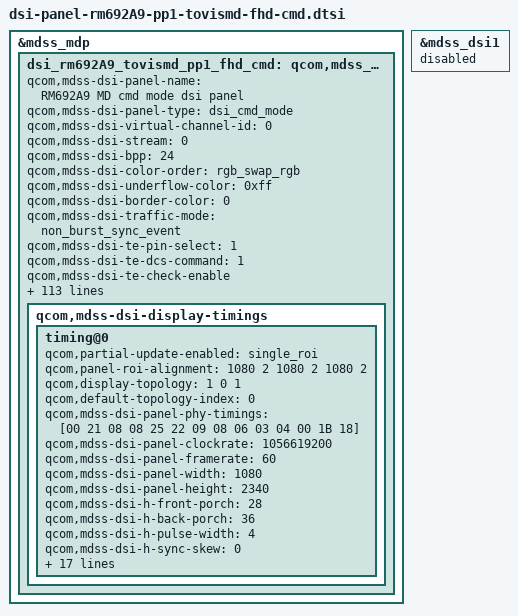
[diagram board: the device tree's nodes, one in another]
/* Copyright (c) 2014, Code Aurora Forum. All rights reserved.
 *
 * This program is free software; you can redistribute it and/or modify
 * it under the terms of the GNU General Public License version 2 and
 * only version 2 as published by the Free Software Foundation.
 *
 * This program is distributed in the hope that it will be useful,
 * but WITHOUT ANY WARRANTY; without even the implied warranty of
 * MERCHANTABILITY or FITNESS FOR A PARTICULAR PURPOSE.  See the
 * GNU General Public License for more details.
 */

&mdss_mdp {
    dsi_rm692A9_tovismd_pp1_fhd_cmd: qcom,mdss_dsi_rm692A9_tovismd_pp1_fhd_cmd {
		qcom,mdss-dsi-panel-name = "RM692A9 MD cmd mode dsi panel";
		qcom,mdss-dsi-panel-type = "dsi_cmd_mode";
		qcom,mdss-dsi-virtual-channel-id = <0>;
		qcom,mdss-dsi-stream = <0>;
		qcom,mdss-dsi-bpp = <24>;
		qcom,mdss-dsi-color-order = "rgb_swap_rgb";
		qcom,mdss-dsi-underflow-color = <0xff>;
		qcom,mdss-dsi-border-color = <0>;
		qcom,mdss-dsi-traffic-mode = "non_burst_sync_event";
		qcom,mdss-dsi-te-pin-select = <1>;
		qcom,mdss-dsi-te-dcs-command = <1>;
		qcom,mdss-dsi-te-check-enable;
		qcom,mdss-dsi-te-using-te-pin;
		qcom,mdss-dsi-lane-map = "lane_map_0123";
		qcom,mdss-dsi-bllp-eof-power-mode;
		qcom,mdss-dsi-bllp-power-mode;
		qcom,mdss-dsi-lane-0-state;
		qcom,mdss-dsi-lane-1-state;
		qcom,mdss-dsi-lane-2-state;
		qcom,mdss-dsi-lane-3-state;
		qcom,mdss-dsi-reset-sequence = <1 10>, <0 2>, <1 10>;
		qcom,mdss-dsi-dma-trigger = "trigger_sw";
		qcom,mdss-dsi-mdp-trigger = "none";
		qcom,mdss-dsi-wr-mem-start = <0x2c>;
		qcom,mdss-dsi-wr-mem-continue = <0x3c>;
		qcom,mdss-dsi-lp11-init;
		qcom,mdss-dsi-tx-eot-append;
		qcom,ulps-enabled;
		qcom,mdss-dsi-panel-hdr-enabled;
		qcom,mdss-dsi-panel-hdr-color-primaries = <14880 15935 32435 16555 14945 30910 7790 3415>;
		qcom,mdss-dsi-panel-peak-brightness = <5643000>;
		qcom,mdss-dsi-panel-blackness-level = <6134>;
		qcom,esd-check-enabled;
		qcom,mdss-dsi-panel-status-check-mode = "te_signal_check";

		lge,blmap = <
			0
			7 7 7 7 7 7 7 7 7 7 7 8 8 9 9 10 10 11 11 12
			12 13 13 13 14 14 15 15 16 16 17 17 18 18 19 19 21 22 24 26
			28 29 31 33 34 36 38 40 41 43 45 47 48 50 52 53 55 57 59 60
			62 65 68 71 75 78 81 84 87 90 93 96 100 103 106 109 112 115 118 121
			125 129 134 139 137 142 147 151 156 161 166 171 176 180 185 190 195 200 205 209
			214 219 224 229 234 238 243 248 254 259 265 270 276 282 287 293 299 304 310 315
			321 327 332 338 343 349 355 360 366 372 377 383 388 394 402 410 418 426 434 442
			449 455 463 471 479 487 495 503 510 518 526 534 542 550 558 566 574 582 592 601
			611 620 629 639 648 657 667 676 685 695 704 713 723 732 741 751 760 769 779 788
			797 807 816 828 840 852 864 876 888 900 912 924 936 948 960 972 984 996 1008 1020
			1032 1044 1056 1068 1080 1092 1104 1117 1130 1143 1156 1170 1183 1196 1209 1222 1235 1248 1261 1275
			1288 1301 1314 1327 1340 1353 1366 1380 1393 1406 1419 1432 1448 1464 1480 1497 1513 1529 1545 1561
			1577 1593 1609 1626 1642 1658 1674 1690 1706 1722 1738 1755 1771 1787 1803 1806 1809 1812 1816 1819
			1822 1825 1828 1831 1834 1837 1841 1844 1847 1850 1853 1856 1859 1862 1866 1869 1872 1875 1878 1881
			1884 1887 1891 1894 1897 1900 1925 1950 1975 2000 2025 2050 2075 2100 2125 2150 2175 2200 2225 2250
			2275 2300 2311 2322 2333 2344 2356 2367 2378 2389 2400 2411 2422 2433 2444 2456 2467 2478 2489 2500
			2538 2577 2615 2654 2692 2731 2769 2808 2846 2885 2923 2962 3000 3038 3077 3115 3154 3192 3231 3269
			3308 3346 3385 3423 3462 3500 3531 3563 3594 3625 3657 3688 3719 3751 3782 3813 3844 3876 3907 3938
			3970 4001 4032 4064 4095
			>;
		lge,blmap-ve = <
			0
			7 7 7 7 7 7 7 7 7 7 7 8 8 9 9 10 10 11 11 12
			12 13 13 13 14 14 15 15 16 16 17 17 18 18 19 19 21 22 24 26
			28 29 31 33 34 36 38 40 41 43 45 47 48 50 52 53 55 57 59 60
			62 65 68 71 75 78 81 84 87 90 93 96 100 103 106 109 112 115 118 121
			125 129 134 139 137 142 147 151 156 161 166 171 176 180 185 190 195 200 205 209
			214 219 224 229 234 238 243 248 254 259 265 270 276 282 287 293 299 304 310 315
			321 327 332 338 343 349 355 360 366 372 377 383 388 394 402 410 418 426 434 442
			449 455 463 471 479 487 495 503 510 518 526 534 542 550 558 566 574 582 592 601
			611 620 629 639 648 657 667 676 685 695 704 713 723 732 741 751 760 769 779 788
			797 807 816 828 840 852 864 876 888 900 912 924 936 948 960 972 984 996 1008 1020
			1032 1044 1056 1068 1080 1092 1104 1117 1130 1143 1156 1170 1183 1196 1209 1222 1235 1248 1261 1275
			1288 1301 1314 1327 1340 1353 1366 1380 1393 1406 1419 1432 1448 1464 1480 1497 1513 1529 1545 1561
			1577 1593 1609 1626 1642 1658 1674 1690 1706 1722 1738 1755 1771 1787 1803 1806 1809 1812 1816 1819
			1822 1825 1828 1831 1834 1837 1841 1844 1847 1850 1853 1856 1859 1862 1866 1869 1872 1875 1878 1881
			1884 1887 1891 1894 1897 1900 1925 1950 1975 2000 2025 2050 2075 2100 2125 2150 2175 2200 2225 2250
			2275 2300 2311 2322 2333 2344 2356 2367 2378 2389 2400 2411 2422 2433 2444 2456 2467 2478 2489 2500
			2538 2577 2615 2654 2692 2731 2769 2808 2846 2885 2923 2962 3000 3038 3077 3115 3154 3192 3231 3269
			3308 3346 3385 3423 3462 3500 3531 3563 3594 3625 3657 3688 3719 3751 3782 3813 3844 3876 3907 3938
			3970 4001 4032 4064 4095
			>;
		lge,blmap-ex = <
			0
			2 2 2 2 2 2 2 2 2 3 4 5 6 7 8 10 11 12 13 14
			15 16 17 18 19 20 21 22 23 25 26 27 28 29 30 31 35 38 42 45
			49 52 56 59 63 66 70 73 77 80 84 87 91 94 98 101 105 108 112 115
			119 122 126 129 133 136 140 143 147 150 154 157 161 164 168 172 176 180 184 188
			192 196 200 204 208 212 215 219 223 227 231 235 239 243 247 251 255 255 255 255
			255 255 255 255 255 255 255 255 255 255 255 255 255 255 255 255 255 255 255 255
			255 255 255 255 255 255 255 255 255 255 255 255 255 255 255 255 255 255 255 255
			255 255 255 255 255 255 255 255 255 255 255 255 255 255 255 255 255 255 255
		>;
		lge,blmap-hdr = <
			0
			7 7 7 7 7 7 7 7 7 7 7 8 8 9 9 10 10 11 11 12
			12 13 13 13 14 14 15 15 16 16 17 17 18 18 19 19 21 22 24 26
			28 29 31 33 34 36 38 40 41 43 45 47 48 50 52 53 55 57 59 60
			62 65 68 71 75 78 81 84 87 90 93 96 100 103 106 109 112 115 118 121
			125 129 134 139 137 142 147 151 156 161 166 171 176 180 185 190 195 200 205 209
			214 219 224 229 234 238 243 248 254 259 265 270 276 282 287 293 299 304 310 315
			321 327 332 338 343 349 355 360 366 372 377 383 388 394 402 410 418 426 434 442
			449 455 463 471 479 487 495 503 510 518 526 534 542 550 558 566 574 582 592 601
			611 620 629 639 648 657 667 676 685 695 704 713 723 732 741 751 760 769 779 788
			797 807 816 828 840 852 864 876 888 900 912 924 936 948 960 972 984 996 1008 1020
			1032 1044 1056 1068 1080 1092 1104 1117 1130 1143 1156 1170 1183 1196 1209 1222 1235 1248 1261 1275
			1288 1301 1314 1327 1340 1353 1366 1380 1393 1406 1419 1432 1448 1464 1480 1497 1513 1529 1545 1561
			1577 1593 1609 1626 1642 1658 1674 1690 1706 1722 1738 1755 1771 1787 1803 1806 1809 1812 1816 1819
			1822 1825 1828 1831 1834 1837 1841 1844 1847 1850 1853 1856 1859 1862 1866 1869 1872 1875 1878 1881
			1884 1887 1891 1894 1897 1900 1925 1950 1975 2000 2025 2050 2075 2100 2125 2150 2175 2200 2225 2250
			2275 2300 2311 2322 2333 2344 2356 2367 2378 2389 2400 2411 2422 2433 2444 2456 2467 2478 2489 2500
			2538 2577 2615 2654 2692 2731 2769 2808 2846 2885 2923 2962 3000 3038 3077 3115 3154 3192 3231 3269
			3308 3346 3385 3423 3462 3500 3531 3563 3594 3625 3657 3688 3719 3751 3782 3813 3844 3876 3907 3938
			3970 4001 4032 4064 4095
		>;
		qcom,mdss-pan-physical-width-dimension = <68>;
		qcom,mdss-pan-physical-height-dimension = <142>;

		qcom,mdss-dsi-t-clk-post = <0x18>;
		qcom,mdss-dsi-t-clk-pre = <0x1B>;

		lge,use-ambient;
		lge,aod-interface-data = "semi-partial", "semi-partial", "semi-partial";
		lge,mdss-dsi-nolp-command = [
			15 01 00 00 00 00 02 FE 00
			05 01 00 00 64 00 01 38
			05 01 00 00 20 00 01 28
			15 01 00 00 00 00 02 FE D0
			15 01 00 00 14 00 02 30 00
			15 01 00 00 00 00 02 FE 20
			15 01 00 00 00 00 02 5F 01
			15 01 00 00 00 00 02 FE 00
			05 01 00 00 20 00 01 29
		];
		lge,mdss-dsi-nolp-command-state = "dsi_lp_mode";

//		lge,mdss-dsi-aod-area-command = [
//			15 01 00 00 00 00 02 FE 00
//			39 01 00 00 00 00 05 30 00 00 04 37
//		];
//		lge,mdss-dsi-aod-area-command-state = "dsi_lp_mode";

		lge,mdss-dsi-lp2-command = [
			15 01 00 00 00 00 02 FE 00
			05 01 00 00 20 00 01 28
			15 01 00 00 00 00 02 FE D0
			15 01 00 00 14 00 02 30 03
			15 01 00 00 00 00 02 FE 20
			15 01 00 00 00 00 02 5F 07
			15 01 00 00 00 00 02 FE 00
			05 01 00 00 64 00 01 29
			05 01 00 00 20 00 01 39
		];
		lge,mdss-dsi-lp2-command-state = "dsi_lp_mode";

		lge,use-line-detect;
		lge,detect-vert-line-restore-command = [
			15 01 00 00 00 00 02 FE 40
			15 01 00 00 00 00 02 2D 28
			15 01 00 00 00 00 02 2F 28
			15 01 00 00 00 00 02 30 32
			15 01 00 00 00 00 02 31 32
			15 01 00 00 00 00 02 FE 00
		];
		lge,detect-vert-line-restore-command-state = "dsi_lp_mode";
		lge,detect-black-vert-line-command = [
			15 01 00 00 00 00 02 FE 40
			15 01 00 00 00 00 02 2D 14
			15 01 00 00 00 00 02 2F 14
			15 01 00 00 00 00 02 30 46
			15 01 00 00 00 00 02 31 46
			15 01 00 00 00 00 02 FE 00
		];
		lge,detect-black-vert-line-command-state = "dsi_lp_mode";
		lge,detect-white-vert-line-command = [
			15 01 00 00 00 00 02 FE 40
			15 01 00 00 00 00 02 2D 46
			15 01 00 00 00 00 02 2F 46
			15 01 00 00 00 00 02 30 1E
			15 01 00 00 00 00 02 31 1E
			15 01 00 00 00 00 02 FE 00
		];
		lge,detect-white-vert-line-command-state = "dsi_lp_mode";

		lge,use-color-manager;
		lge,color-manager-default-status = <1>;
		lge,mdss-dsi-color-manager-mode-table = <0 1>, <1 1>, <2 1>, <3 1>;
		lge,digital-gamma-absent;

		lge,mdss-dsi-disp-ctrl-command-1 = [
			15 01 00 00 00 00 02 FE 00
			15 01 00 00 00 00 02 5C 00
			15 01 00 00 00 00 02 FE 80
			15 01 00 00 00 00 02 00 4F
			15 01 00 00 00 00 02 05 00
			15 01 00 00 00 00 02 FE 00
		];
		lge,mdss-dsi-disp-ctrl-command-1-state = "dsi_lp_mode";
		lge,mdss-dsi-disp-ctrl-command-2 = [
			15 01 00 00 00 00 02 FE 12
			15 01 00 00 00 00 02 83 10
			15 01 00 00 00 00 02 84 08
			15 01 00 00 00 00 02 FE 00
		];
		lge,mdss-dsi-disp-ctrl-command-2-state = "dsi_lp_mode";

		lge,color-mode-cmds-dummy = [
			/* CE setting */
			15 00 00 00 00 00 02 FE 00
			15 00 00 00 00 00 02 5A 0B
			15 00 00 00 00 00 02 5C 00
			/* HUE, SAT enable/disable */
			15 00 00 00 00 00 02 FE 80
			15 00 00 00 00 00 02 00 4F
			/* CE gain */
			15 00 00 00 00 00 02 08 44
			15 00 00 00 00 00 02 09 20
			15 00 00 00 00 00 02 0A EE
			15 00 00 00 00 00 02 0B 02
			15 00 00 00 00 00 02 0C 20
			15 00 00 00 00 00 02 0D F0
			15 00 00 00 00 00 02 0E CF
			15 00 00 00 00 00 02 0F 07
			15 00 00 00 00 00 02 14 CF
			15 00 00 00 00 00 02 15 04
			15 00 00 00 00 00 02 16 F3
			15 00 00 00 00 00 02 17 D7
			15 00 00 00 00 00 02 18 CC
			15 00 00 00 00 00 02 19 7D
			15 00 00 00 00 00 02 1A E3
			15 00 00 00 00 00 02 1B 07
			/* Default CM */
			15 00 00 00 00 00 02 FE 10
			15 00 00 00 00 00 02 00 FF
			15 00 00 00 00 00 02 01 07
			15 00 00 00 00 00 02 02 00
			15 00 00 00 00 00 02 03 00
			15 00 00 00 00 00 02 04 00
			15 00 00 00 00 00 02 05 00
			15 00 00 00 00 00 02 06 FF
			15 00 00 00 00 00 02 07 E7
			15 00 00 00 00 00 02 08 00
			15 00 00 00 00 00 02 09 03
			15 00 00 00 00 00 02 0A 20
			15 00 00 00 00 00 02 0B 00
			15 00 00 00 00 00 02 0C FC
			15 00 00 00 00 00 02 0D 07
			15 00 00 00 00 00 02 FE 12
			15 00 00 00 00 00 02 84 08
			15 01 00 00 00 00 02 FE 00
		];
		lge,color-mode-cmds-dummy-state = "dsi_lp_mode";

		lge,use-color-manager-lut;
		lge,cm-lut-screen-mode-set-name = "def", "cin", "pho", "web", "spo", "gam", "exp";
		lge,cm-lut-screen-mode-set-cnt = <39>;
		lge,cm-lut-screen-mode-set = [
			00 0B 00 80 4F 44 20 EE 02 20 F0 CF 07 CF 04 F3 D7 CC 7D E3 07 10 FF 07 00 00 00 00 FF E7 00 03 20 00 FC 07 12 08 00
			00 0B 00 80 4F 00 FF FF 00 F0 EF C3 01 0F 0F 03 D2 EE 3F 85 07 10 53 07 08 3B 90 00 23 77 02 00 90 00 9F 06 12 00 00
			00 0B 00 80 4F F0 F0 C0 C0 22 F2 55 07 1F 00 03 43 00 EF 01 0C 10 FF 07 00 35 90 06 BD 46 02 28 80 03 46 06 12 00 00
			00 0B 00 80 4F F0 FF F0 00 FF FF D1 00 0F 0F 03 02 00 1F 05 04 10 0D 56 1E 36 F0 04 E1 36 02 1D 00 08 07 06 12 00 00
			00 0B 00 80 4F 46 22 EE 15 21 F0 CF 07 CF 04 F3 C7 CC 7D E3 07 10 2E 07 00 00 00 00 40 E7 00 03 30 00 FB 07 12 00 00
			00 0B 00 80 4F 46 40 FE 12 21 F0 CF 07 CF 04 F3 C7 CC 7D E3 07 10 7F 07 00 00 00 00 95 D7 00 03 30 00 FA 07 12 00 00
			00 0B 00 80 4F 44 20 EE 02 20 F0 CF 07 CF 04 F3 D7 CC 7D E3 07 10 FF 07 00 00 00 00 FF E7 00 03 20 00 FC 07 12 08 00
		];

		lge,cm-lut-saturation-cnt = <13>;
		lge,cm-lut-saturation = [
			00 0B 00 80 4F D9 DD DC DD DD CD 01 00
			00 0B 00 80 4F EC EF FE FF FF DF 01 00
			00 0B 00 80 4F 44 20 EE 02 20 F0 CF 07
			00 0B 00 80 4F FF 44 FF 23 44 B2 CD 0F
			00 0B 00 80 4F 1F 56 01 56 56 F3 FF 0F
		];

		lge,cm-lut-sharpness-cnt = <1>;
		lge,cm-lut-sharpness = [08 12 1C 26 30];

		lge,cm-lut-rgb-hue-cnt = <14>;
		lge,cm-lut-rgb-hue = [
			E0 25 01 F5 20 09 72 47 00 01 00 0C 50 06
			80 26 01 F5 20 09 72 A7 00 01 00 0C C0 06
			F0 26 01 F5 20 09 73 07 00 01 00 0C 40 07
			FF 26 01 F5 20 09 11 87 00 01 00 0C 3A 07
			FF 26 01 F5 20 09 7F 86 00 01 00 0C 30 07
			5A 06 01 7E 00 05 B8 47 00 00 F0 05 A4 06
			E8 06 01 7E 00 05 CF A7 00 00 F0 05 17 07
			68 07 01 7E 00 05 B9 07 00 00 F0 05 A3 07
			30 07 01 7E 00 05 00 87 00 00 F0 05 4F 07
			30 07 01 7E 00 05 84 96 00 00 F0 05 3F 07
			EB 06 00 00 00 00 FF 67 00 00 30 00 04 07
			77 07 00 00 00 00 FF 77 00 01 30 00 7C 07
			FF 07 00 00 00 00 FF E7 00 03 20 00 FC 07
			FF 07 00 00 00 00 9B 77 00 01 30 00 F4 07
			FF 07 00 00 00 00 21 87 00 01 30 00 F4 07
			35 06 0A 00 40 01 8F 67 04 43 E0 00 99 06
			C0 06 0A 00 40 01 8F 77 04 43 E0 00 10 07
			60 07 0A 00 40 01 8F E7 04 43 E0 00 B0 07
			60 07 0A 00 40 01 50 77 04 43 E0 00 AF 07
			60 07 0A 00 40 01 DE 76 04 43 E0 00 A7 07
			BA 75 12 00 F0 00 5D 67 08 7F E0 00 69 06
			4A 76 12 00 F0 00 5D 77 08 7F E0 00 DE 06
			EA 76 12 00 F0 00 5D E7 08 7F E0 00 73 07
			EA 76 12 00 F0 00 16 77 08 7F E0 00 70 07
			EA 76 12 00 F0 00 97 76 08 7F E0 00 6A 07
		];

		/* Video Enahnacement */
		lge,mdss-dsi-ve-on-command = [
			15 01 00 00 00 00 02 FE 00
			15 01 00 00 00 00 02 6A A8
		];
		lge,mdss-dsi-ve-on-command-state = "dsi_lp_mode";

		lge,mdss-dsi-ve-off-command = [
			15 01 00 00 00 00 02 FE 00
			15 01 00 00 00 00 02 6A 50
		];
		lge,mdss-dsi-ve-off-command-state = "dsi_lp_mode";

		lge,disp-br-ctrl-ext-supported;
		lge,ddic-dsi-br-ctrl-ext-command = [
			15 01 00 00 00 00 02 FE 72
			15 01 00 00 00 00 02 69 00
			15 01 00 00 00 00 02 FE 00
		];
		lge,ddic-dsi-br-ctrl-ext-command-state = "dsi_lp_mode";

		/* FP LHBM */
		lge,use-fp-lhbm;
		//lge,is-fp-hbm-mode;
		lge,fp-hbm-mode-backlight-level = <0x70B>;
		lge,mdss-dsi-fp-lhbm-command = [
			15 01 00 00 00 00 02 FE 00
			15 01 00 00 14 00 02 83 00
		];
		lge,mdss-dsi-fp-lhbm-command-state = "dsi_lp_mode";

		lge,mdss-dsi-fp-lhbm-ready-command = [
			15 00 00 00 00 00 02 FE 74
			15 00 00 00 00 00 02 3D FF
			15 00 00 00 00 00 02 46 FF
			15 00 00 00 00 00 02 41 FF
			15 01 00 00 00 00 02 3A FF
			15 00 00 00 00 00 02 FE D0
			15 01 00 00 00 00 02 99 03
			15 01 00 00 00 00 02 FE 00
		];
		lge,mdss-dsi-fp-lhbm-ready-command-state = "dsi_lp_mode";

		lge,mdss-dsi-fp-lhbm-exit-command = [
			15 00 00 00 00 00 02 FE 74 /*LHBM Exit*/
			15 00 00 00 00 00 02 3D 4F
			15 00 00 00 00 00 02 46 00
			15 00 00 00 00 00 02 41 00
			15 01 00 00 00 00 02 3A F4
			15 00 00 00 00 00 02 FE D0
			15 01 00 00 00 00 02 99 01
			15 01 00 00 00 00 02 FE 00
		];
		lge,mdss-dsi-fp-lhbm-exit-command-state = "dsi_lp_mode";

		qcom,mdss-dsi-display-timings {
			timing@0{
				qcom,partial-update-enabled = "single_roi";
				qcom,panel-roi-alignment = <1080 2 1080 2 1080 2>;
				qcom,display-topology = <1 0 1>;
				qcom,default-topology-index = <0>;
				qcom,mdss-dsi-panel-phy-timings = [00 21 08 08 25 22 09 08 06 03 04 00 1B 18];
				qcom,mdss-dsi-panel-clockrate = <1056619200>;
				qcom,mdss-dsi-panel-framerate = <60>;
				qcom,mdss-dsi-panel-width = <1080>;
				qcom,mdss-dsi-panel-height = <2340>;
				qcom,mdss-dsi-h-front-porch = <28>;
				qcom,mdss-dsi-h-back-porch = <36>;
				qcom,mdss-dsi-h-pulse-width = <4>;
				qcom,mdss-dsi-h-sync-skew = <0>;
				qcom,mdss-dsi-v-back-porch = <4>;
				qcom,mdss-dsi-v-front-porch = <12>;
				qcom,mdss-dsi-v-pulse-width = <4>;
				qcom,mdss-dsi-h-left-border = <0>;
				qcom,mdss-dsi-h-right-border = <0>;
				qcom,mdss-dsi-v-top-border = <0>;
				qcom,mdss-dsi-v-bottom-border = <0>;
				qcom,mdss-mdp-transfer-time-us = <15200>;

				qcom,mdss-dsi-on-command = [
					15 00 00 00 00 00 02 FE 40
					15 00 00 00 00 00 02 6F 00
					15 00 00 00 00 00 02 74 51
					15 00 00 00 00 00 02 75 23
					15 00 00 00 00 00 02 80 48
					15 01 00 00 00 00 02 9A 01
					15 00 00 00 00 00 02 FE D0
					15 01 00 00 00 00 02 42 00
					15 00 00 00 00 00 02 FE 70
					15 01 00 00 00 00 02 35 01
					15 00 00 00 00 00 02 FE 40
					15 00 00 00 00 00 02 3B 20
					15 00 00 00 00 00 02 3D 52
					15 01 00 00 00 00 02 6B 40
					15 00 00 00 00 00 02 FE 00
					15 01 00 00 00 00 02 C2 08
					15 01 00 00 00 00 02 35 00
					39 01 00 00 00 00 03 51 00 00
					05 01 00 00 78 00 01 11
				];
				qcom,mdss-dsi-on-command-state = "dsi_lp_mode";

				qcom,mdss-dsi-post-panel-on-command = [
					05 01 00 00 0A 00 01 29
				];

				qcom,mdss-dsi-off-command = [
					05 01 00 00 00 00 01 28
					05 01 00 00 96 00 01 10
				];
				qcom,mdss-dsi-off-command-state = "dsi_lp_mode";
				qcom,mdss-dsi-h-sync-pulse = <0>;
			};
		};
	};
};
/*
&spmi_bus {
	qcom,pmi8998@3 {
		labibb: qpnp-labibb-regulator {
			status = "disabled";
		};
	};
};
*/
&mdss_dsi1 {
	status = "disabled";
};
